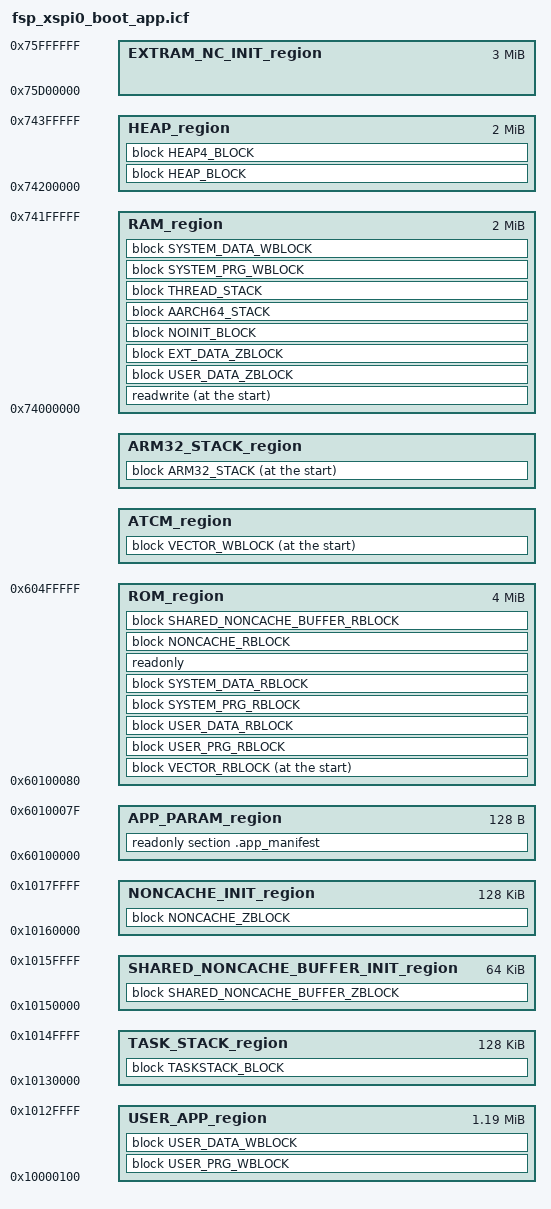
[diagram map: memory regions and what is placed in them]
/*=============================================================================
 * fsp_xspi0_boot_app.icf
 *
 * IAR linker configuration for the App half of the Loader+App split.
 *
 * Strictly aligned with the source rzn2l_xspi_boot.icf "primary" branch in
 * the ATCM-defined + no-USE_HRAM configuration (which is what RZN2L EK52
 * with PROFINET-IRT actually compiles into).
 *
 * Source-compatible blocks are exposed to the Loader through .app_manifest:
 *
 *   APP image in xSPI0 flash @ 0x60100000               Loader copies to
 *   --------------------------------------               -----------------
 *   [.app_manifest 0x80 bytes]                           (read in place)
 *   [VECTOR_RBLOCK]      vector table init       ----->  ATCM @ 0x00000000
 *   [USER_PRG_RBLOCK]    ro code                  ----->  USER_PRG_WBLOCK
 *   [USER_DATA_RBLOCK]   .rodata/.data inits      ----->  USER_DATA_WBLOCK
 *   [SYSTEM_PRG_RBLOCK]  obsd*.o ro code          ----->  SYSTEM_PRG_WBLOCK
 *   [SYSTEM_DATA_RBLOCK] obsd*.o data inits       ----->  SYSTEM_DATA_WBLOCK
 *   [NONCACHE_RBLOCK]    initialized noncache     ----->  NONCACHE_WBLOCK
 *   [SHARED_NONCACHE_BUFFER_RBLOCK]               ----->  SHARED_NONCACHE_BUFFER_WBLOCK
 *   [readonly catch-all]                                 (read in place)
 *
 * Runtime layout (after Loader has finished copying and jumped to 0x00):
 *
 *   ATCM           0x00000000 - 0x0001FFFF  (128 KB)
 *      VECTOR_WBLOCK  (reset vector + 15 exception vectors)
 *
 *   BTCM           0x00100000 - 0x0011FFFF  (128 KB)
 *      0x00103F88  ARM32_STACK (exception mode stacks: SYS/SVC/IRQ/FIQ/UND/ABT)
 *                  SVC_STACK at 0x00104388, matching source project layout
 *
 *   SystemRAM      0x10000000 - 0x1017FFFF  (1.5 MB)
 *      0x10000100  USER_PRG_WBLOCK + USER_DATA_WBLOCK    (USER_APP_region)
 *      0x10130000  TASKSTACK_BLOCK                       (TASK_STACK_region)
 *      0x10150000  SHARED_NONCACHE_BUFFER_*              (source-compatible)
 *      0x10160000  NONCACHE_ZBLOCK / NONCACHE_WBLOCK     (.noncache_buffer*)
 *
 *   SDRAM CS2 cacheable  0x74000000 - 0x77FFFFFF (32 MB W9825G6KH-6)
 *      0x74000000  USER_DATA_ZBLOCK + EXT_DATA_ZBLOCK
 *                  + NOINIT_BLOCK + AARCH64_STACK + THREAD_STACK
 *                                                          (RAM_region, 2 MB)
 *                  + SYSTEM_PRG_WBLOCK + SYSTEM_DATA_WBLOCK
 *      0x74200000  HEAP_BLOCK + HEAP4_BLOCK                (HEAP_region, 2 MB)
 *      0x75D00000  EXTRAMNC_BLOCK (mirrored to 0x55D00000 noncache view)
 *
 *=============================================================================*/

include "memory_regions.icf";

/*-----------------------------------------------------------------------------*/
/*  Symbols / addresses                                                        */
/*-----------------------------------------------------------------------------*/

define symbol APP_FLASH_START          = 0x60100000;
define symbol APP_FLASH_SIZE           = 0x00400000;       /* 4 MB           */

define symbol APP_MANIFEST_SIZE        = 0x00000080;       /* see app_manifest.c */

/* Mirrors source's "ATCM defined, no USE_HRAM" branch:                       */
/*   INTVEC_ADDRESS = ATCM_PRV_START                                          */
/*   USER_APP       = [0x10000100, 0x1012FFFF]   (SystemRAM, ~1.2 MB)         */
/*   TASK_STACK     = [0x10130000, 0x1014FFFF]   (SystemRAM, 128 KB)          */
/*   RAM_region     = [CS2 + 0,    CS2 + 0x1FFFFF] = [0x74000000, 0x741FFFFF] */
/*   HEAP_region    = [0x74200000, 0x743FFFFF]   (2 MB)                       */
/*   EXTRAM_NC      = CS2_top - 0x300000 = 0x75D00000 (mirrored from 0x55D00000) */

define symbol INTVEC_ADDRESS           = ATCM_CR52_0_START;       /* 0x00000000  */
define symbol ATCM_REGION_SIZE         = ATCM_CR52_0_LENGTH;      /* 0x00020000  */

define symbol ARM32_STACK_START        = BTCM_CR52_0_START + 0x00003F88;
define symbol ARM32_STACK_END          = ARM32_STACK_START + 0x000017FF;

define symbol USER_APP_START           = 0x10000100;
define symbol USER_APP_END             = 0x1012FFFF;

define symbol TASK_STACK_START         = 0x10130000;
define symbol TASK_STACK_END           = 0x1014FFFF;

define symbol CS2_BASE                 = 0x74000000;
define symbol RSK_SDRAM_SIZE           = 0x02000000;     /* 32 MB W9825G6KH-6 */
define symbol EXTRAM_NC_SIZE           = 0x00300000;     /* 3 MB              */
define symbol EXTERNAL_RAM_MIRROR_OFFSET = 0x20000000;   /* cached <-> noncache */

define symbol RAM_region_START         = CS2_BASE;                                  /* 0x74000000 */
define symbol RAM_region_END           = CS2_BASE + 0x001FFFFF;                     /* 0x741FFFFF */

define symbol HEAP_region_START        = 0x74200000;
define symbol HEAP_region_END          = 0x743FFFFF;

define symbol NONCACHE_INIT_START      = 0x10160000;
define symbol NONCACHE_INIT_END        = 0x1017FFFF;
define symbol NONCACHE_RUNTIME_START   = 0x30160000;

define symbol SHARED_NONCACHE_INIT_START    = 0x10150000;
define symbol SHARED_NONCACHE_INIT_END      = 0x1015FFFF;
define symbol SHARED_NONCACHE_RUNTIME_START = 0x30150000;

/* EXTRAM_NC runtime sits at the TOP 3 MB of physical SDRAM via the noncache  */
/* CS2 mirror (0x54000000 = CS2 - 0x20000000). The init image lives at the    */
/* same physical SDRAM cells viewed through the cached alias, so IAR can      */
/* link-place the bytes during build.                                         */
define symbol EXTRAM_NC_NC_START       = (CS2_BASE - EXTERNAL_RAM_MIRROR_OFFSET) + RSK_SDRAM_SIZE - EXTRAM_NC_SIZE;
                                                                                    /* 0x55D00000 */
define symbol EXTRAM_NC_C_START        =  CS2_BASE                              + RSK_SDRAM_SIZE - EXTRAM_NC_SIZE;
                                                                                    /* 0x75D00000 */

/*-----------------------------------------------------------------------------*/
/*  Memory + Regions                                                           */
/*-----------------------------------------------------------------------------*/

define memory mem with size = 4G;

define region APP_PARAM_region       = mem:[from APP_FLASH_START                     size APP_MANIFEST_SIZE];
define region ROM_region             = mem:[from APP_FLASH_START + APP_MANIFEST_SIZE  size APP_FLASH_SIZE - APP_MANIFEST_SIZE];
define region ATCM_region            = mem:[from INTVEC_ADDRESS                      size ATCM_REGION_SIZE];
define region ARM32_STACK_region     = mem:[from ARM32_STACK_START                   to   ARM32_STACK_END];
define region USER_APP_region        = mem:[from USER_APP_START                      to   USER_APP_END];
define region TASK_STACK_region      = mem:[from TASK_STACK_START                    to   TASK_STACK_END];
define region RAM_region             = mem:[from RAM_region_START                    to   RAM_region_END];
define region HEAP_region            = mem:[from HEAP_region_START                   to   HEAP_region_END];
define region NONCACHE_INIT_region   = mem:[from NONCACHE_INIT_START                 to   NONCACHE_INIT_END];
define region SHARED_NONCACHE_BUFFER_INIT_region = mem:[from SHARED_NONCACHE_INIT_START to SHARED_NONCACHE_INIT_END];
define region EXTRAM_NC_INIT_region  = mem:[from EXTRAM_NC_C_START                   size EXTRAM_NC_SIZE];

/*=============================================================================*/
/*  B L O C K   L A Y O U T                                                    */
/*=============================================================================*/

/*-----------------------------------------------------------------------------*/
/*  Vector table (16 entries x 0x80)                                           */
/*-----------------------------------------------------------------------------*/

define block VECTOR_RBLOCK with fixed order
{
    block VECTOR_RBLOCK_0x000 with alignment = 0x80 { ro code section .intvec_init       },
    block VECTOR_RBLOCK_0x080 with alignment = 0x80 { ro code section .intvec_0x080_init },
    block VECTOR_RBLOCK_0x100 with alignment = 0x80 { ro code section .intvec_0x100_init },
    block VECTOR_RBLOCK_0x180 with alignment = 0x80 { ro code section .intvec_0x180_init },
    block VECTOR_RBLOCK_0x200 with alignment = 0x80 { ro code section .intvec_0x200_init },
    block VECTOR_RBLOCK_0x280 with alignment = 0x80 { ro code section .intvec_0x280_init },
    block VECTOR_RBLOCK_0x300 with alignment = 0x80 { ro code section .intvec_0x300_init },
    block VECTOR_RBLOCK_0x380 with alignment = 0x80 { ro code section .intvec_0x380_init },
    block VECTOR_RBLOCK_0x400 with alignment = 0x80 { ro code section .intvec_0x400_init },
    block VECTOR_RBLOCK_0x480 with alignment = 0x80 { ro code section .intvec_0x480_init },
    block VECTOR_RBLOCK_0x500 with alignment = 0x80 { ro code section .intvec_0x500_init },
    block VECTOR_RBLOCK_0x580 with alignment = 0x80 { ro code section .intvec_0x580_init },
    block VECTOR_RBLOCK_0x600 with alignment = 0x80 { ro code section .intvec_0x600_init },
    block VECTOR_RBLOCK_0x680 with alignment = 0x80 { ro code section .intvec_0x680_init },
    block VECTOR_RBLOCK_0x700 with alignment = 0x80 { ro code section .intvec_0x700_init },
    block VECTOR_RBLOCK_0x780 with alignment = 0x80 { ro code section .intvec_0x780_init }
};

define block VECTOR_WBLOCK with fixed order
{
    block VECTOR_WBLOCK_0x000 with alignment = 0x80 { rw code section .intvec       },
    block VECTOR_WBLOCK_0x080 with alignment = 0x80 { rw code section .intvec_0x080 },
    block VECTOR_WBLOCK_0x100 with alignment = 0x80 { rw code section .intvec_0x100 },
    block VECTOR_WBLOCK_0x180 with alignment = 0x80 { rw code section .intvec_0x180 },
    block VECTOR_WBLOCK_0x200 with alignment = 0x80 { rw code section .intvec_0x200 },
    block VECTOR_WBLOCK_0x280 with alignment = 0x80 { rw code section .intvec_0x280 },
    block VECTOR_WBLOCK_0x300 with alignment = 0x80 { rw code section .intvec_0x300 },
    block VECTOR_WBLOCK_0x380 with alignment = 0x80 { rw code section .intvec_0x380 },
    block VECTOR_WBLOCK_0x400 with alignment = 0x80 { rw code section .intvec_0x400 },
    block VECTOR_WBLOCK_0x480 with alignment = 0x80 { rw code section .intvec_0x480 },
    block VECTOR_WBLOCK_0x500 with alignment = 0x80 { rw code section .intvec_0x500 },
    block VECTOR_WBLOCK_0x580 with alignment = 0x80 { rw code section .intvec_0x580 },
    block VECTOR_WBLOCK_0x600 with alignment = 0x80 { rw code section .intvec_0x600 },
    block VECTOR_WBLOCK_0x680 with alignment = 0x80 { rw code section .intvec_0x680 },
    block VECTOR_WBLOCK_0x700 with alignment = 0x80 { rw code section .intvec_0x700 },
    block VECTOR_WBLOCK_0x780 with alignment = 0x80 { rw code section .intvec_0x780 }
};

/*-----------------------------------------------------------------------------*/
/*  USER program: FSP drivers + application glue (SRAM-resident)               */
/*  Everything except obsd* PROFINET stack and a few special sections.         */
/*-----------------------------------------------------------------------------*/

define block USER_PRG_RBLOCK with alignment = 8
{
    ro code
}
except
{
    ro code object obsd*.o,
    ro code section .intvec_init,
    ro code section .intvec_0x080_init, ro code section .intvec_0x100_init,
    ro code section .intvec_0x180_init, ro code section .intvec_0x200_init,
    ro code section .intvec_0x280_init, ro code section .intvec_0x300_init,
    ro code section .intvec_0x380_init, ro code section .intvec_0x400_init,
    ro code section .intvec_0x480_init, ro code section .intvec_0x500_init,
    ro code section .intvec_0x580_init, ro code section .intvec_0x600_init,
    ro code section .intvec_0x680_init, ro code section .intvec_0x700_init,
    ro code section .intvec_0x780_init
};

define block USER_PRG_WBLOCK with alignment = 8
{
    rw code
}
except
{
    rw code object obsd*.o,
    rw code section .intvec,
    rw code section .intvec_0x080, rw code section .intvec_0x100,
    rw code section .intvec_0x180, rw code section .intvec_0x200,
    rw code section .intvec_0x280, rw code section .intvec_0x300,
    rw code section .intvec_0x380, rw code section .intvec_0x400,
    rw code section .intvec_0x480, rw code section .intvec_0x500,
    rw code section .intvec_0x580, rw code section .intvec_0x600,
    rw code section .intvec_0x680, rw code section .intvec_0x700,
    rw code section .intvec_0x780
};

define block USER_DATA_RBLOCK with fixed order, alignment = 8
{
    block USER_DATA_RBLOCK0 with alignment = 8 { section .rodata_init         },
    block USER_DATA_RBLOCK1 with alignment = 8 { section __DLIB_PERTHREAD_init },
    block USER_DATA_RBLOCK2 with alignment = 8 { section .data_init           },
    block USER_DATA_RBLOCK3 with alignment = 8 { section .version_init        }
}
except
{
    section .rodata_init       object obsd*.o,
    section .data_init         object obsd*.o
};

define block USER_DATA_WBLOCK with fixed order, alignment = 8
{
    block USER_DATA_WBLOCK0 with alignment = 8 { section .rodata          },
    block USER_DATA_WBLOCK1 with alignment = 8 { section __DLIB_PERTHREAD },
    block USER_DATA_WBLOCK2 with alignment = 8 { section .data            },
    block USER_DATA_WBLOCK3 with alignment = 8 { section .version         }
}
except
{
    section .rodata object obsd*.o,
    section .data   object obsd*.o
};

/*-----------------------------------------------------------------------------*/
/*  SYSTEM program: PROFINET (obsd*.o) - SDRAM-resident (bulky)                */
/*-----------------------------------------------------------------------------*/

define block SYSTEM_PRG_RBLOCK with alignment = 8
{
    ro code object obsd*.o
};

define block SYSTEM_PRG_WBLOCK with alignment = 8
{
    rw code object obsd*.o
};

define block SYSTEM_DATA_RBLOCK with fixed order, alignment = 8
{
    block SYSTEM_DATA_RBLOCK0 with alignment = 8 { section .rodata_init object obsd*.o },
    block SYSTEM_DATA_RBLOCK1 with alignment = 8 { section .data_init   object obsd*.o }
};

define block SYSTEM_DATA_WBLOCK with fixed order, alignment = 8
{
    block SYSTEM_DATA_WBLOCK0 with alignment = 8 { section .rodata object obsd*.o },
    block SYSTEM_DATA_WBLOCK1 with alignment = 8 { section .data   object obsd*.o }
};

/*-----------------------------------------------------------------------------*/
/*  Zero-init / uninitialised / stack blocks                                   */
/*-----------------------------------------------------------------------------*/

define block USER_DATA_ZBLOCK with alignment = 8 { };
define block EXT_DATA_ZBLOCK  with alignment = 4 { section .bss, section xdata_d_tcm };
define block NOINIT_BLOCK     with alignment = 8 { zeroinit };

define block ARM32_STACK with fixed order
{
    block SYS_STACK with alignment = 8 { rw section .sys_stack },
    block SVC_STACK with alignment = 8 { rw section .svc_stack },
    block IRQ_STACK with alignment = 8 { rw section .irq_stack },
    block FIQ_STACK with alignment = 8 { rw section .fiq_stack },
    block UND_STACK with alignment = 8 { rw section .und_stack },
    block ABT_STACK with alignment = 8 { rw section .abt_stack }
};
define block AARCH64_STACK   with alignment = 8 { rw section .aarch64_stack* };
define block THREAD_STACK    with alignment = 8 { rw section .stack*         };
define block TASKSTACK_BLOCK with alignment = 4 { section task_stack         };

define block HEAP_BLOCK   with alignment = 8 { rw section HEAP              };
define block HEAP4_BLOCK  with alignment = 4 { section .bss object heap_4.o };

define block EXTRAMNC_BLOCK with alignment = 32 { section nocache, section uncached_mem };

/*-----------------------------------------------------------------------------*/
/*  NONCACHE blocks, matching source rzn2l_xspi_boot.icf naming.              */
/*-----------------------------------------------------------------------------*/

define block NONCACHE_RBLOCK with fixed order, alignment = 32
{
    block USER_DATA_NONCACHE_RBLOCK with alignment = 8 { section .data_noncache*_init },
    block DMAC_LINK_MODE_RBLOCK with alignment = 8 { section .dmac_link_mode*_init },
    block NONCACHE_BUFFER_RBLOCK with alignment = 32 { section .noncache_buffer*_init }
};

define block NONCACHE_WBLOCK with fixed order
{
    block USER_DATA_NONCACHE_WBLOCK with alignment = 8 { section .data_noncache* },
    block DMAC_LINK_MODE_WBLOCK with alignment = 8 { section .dmac_link_mode* },
    block NONCACHE_BUFFER_WBLOCK with alignment = 32 { section .noncache_buffer* }
};

define block NONCACHE_ZBLOCK with fixed order
{
    block USER_DATA_NONCACHE_ZBLOCK with alignment = 8 { zi section .data_noncache* },
    block DMAC_LINK_MODE_ZBLOCK with alignment = 8 { zi section .dmac_link_mode* },
    block NONCACHE_BUFFER_ZBLOCK with alignment = 32 { zi section .noncache_buffer* }
};

define block SHARED_NONCACHE_BUFFER_RBLOCK with alignment = 32 { section .shared_noncache_buffer*_init };
define block SHARED_NONCACHE_BUFFER_WBLOCK with alignment = 32 { section .shared_noncache_buffer* };
define block SHARED_NONCACHE_BUFFER_ZBLOCK with alignment = 32 { zi section .shared_noncache_buffer* };

/*=============================================================================*/
/*  S P E C I F Y I N G   I N I T I A L I Z A T I O N                          */
/*=============================================================================*/

initialize manually
{
    ro code,
    section .data,
    section __DLIB_PERTHREAD,
    section .rodata,
    section .version,
    section .data_noncache*,
    section .dmac_link_mode*,
    section .noncache_buffer*,
    section .shared_noncache_buffer*,
    section .data_extramnc*
};

do not initialize { zeroinit, section .noinit };

/*=============================================================================*/
/*  S E C T I O N   L A Y O U T                                                */
/*=============================================================================*/

/*-----------------------------------------------------------------------------*/
/*  Flash (xSPI0 CS0)                                                          */
/*  Order:                                                                     */
/*    [0x60100000] .app_manifest    (128 bytes, read in place by Loader)       */
/*    [0x60100080] VECTOR_RBLOCK    (vector table init image)                  */
/*                USER_PRG_RBLOCK / USER_DATA_RBLOCK                           */
/*                SYSTEM_PRG_RBLOCK / SYSTEM_DATA_RBLOCK                       */
/*                NONCACHE_RBLOCK / SHARED_NONCACHE_BUFFER_RBLOCK              */
/*                readonly catch-all                                           */
/*-----------------------------------------------------------------------------*/

place in APP_PARAM_region          { readonly section .app_manifest };

place at start of ROM_region       { block VECTOR_RBLOCK };
place in ROM_region                {
    block USER_PRG_RBLOCK,
    block USER_DATA_RBLOCK,
    block SYSTEM_PRG_RBLOCK,
    block SYSTEM_DATA_RBLOCK,
    readonly,
    block NONCACHE_RBLOCK,
    block SHARED_NONCACHE_BUFFER_RBLOCK
};

/*-----------------------------------------------------------------------------*/
/*  ATCM @ 0x00000000   (vector table runtime location, matches source ATCM    */
/*                       branch INTVEC_ADDRESS = ATCM_PRV_START)               */
/*-----------------------------------------------------------------------------*/

place at start of ATCM_region      { block VECTOR_WBLOCK };

/*-----------------------------------------------------------------------------*/
/*  SystemRAM   USER_APP_region = 0x10000100 - 0x1012FFFF                      */
/*-----------------------------------------------------------------------------*/

place in USER_APP_region           { block USER_PRG_WBLOCK };
place in USER_APP_region           { block USER_DATA_WBLOCK };

place at start of ARM32_STACK_region
                                   { block ARM32_STACK };

place in TASK_STACK_region         { block TASKSTACK_BLOCK };

/*-----------------------------------------------------------------------------*/
/*  SDRAM (CS2 cacheable)                                                      */
/*    RAM_region [0x74000000, 0x741FFFFF]:                                     */
/*      zero-init blocks + AArch64/thread stacks + SYSTEM_PRG/DATA_WBLOCK      */
/*    HEAP_region [0x74200000, 0x743FFFFF]:                                    */
/*      HEAP_BLOCK + HEAP4_BLOCK                                               */
/*    EXTRAM_NC_INIT_region [0x75D00000, 0x75FFFFFF]:                          */
/*      EXTRAMNC_BLOCK (mirrored to 0x55D00000 noncache view)                  */
/*-----------------------------------------------------------------------------*/

place at start of RAM_region       { readwrite };

place in RAM_region
{
    block USER_DATA_ZBLOCK,
    block EXT_DATA_ZBLOCK,
    block NOINIT_BLOCK,
    block AARCH64_STACK,
    block THREAD_STACK
};

place in RAM_region                { block SYSTEM_PRG_WBLOCK };
place in RAM_region                { block SYSTEM_DATA_WBLOCK };

place in HEAP_region               { block HEAP_BLOCK, block HEAP4_BLOCK };

place in NONCACHE_INIT_region with mirroring to NONCACHE_RUNTIME_START
                                   { block NONCACHE_WBLOCK };
place in NONCACHE_INIT_region      { block NONCACHE_ZBLOCK };

place in SHARED_NONCACHE_BUFFER_INIT_region with mirroring to SHARED_NONCACHE_RUNTIME_START
                                   { block SHARED_NONCACHE_BUFFER_WBLOCK };
place in SHARED_NONCACHE_BUFFER_INIT_region
                                   { block SHARED_NONCACHE_BUFFER_ZBLOCK };

place in EXTRAM_NC_INIT_region with mirroring to EXTRAM_NC_NC_START
                                   { block EXTRAMNC_BLOCK };

/*=============================================================================*/
/*  E X P O R T E D   S Y M B O L S                                            */
/*=============================================================================*/

define exported symbol __region_APP_FLASH_start__  = APP_FLASH_START;
define exported symbol __region_INTVEC_start__     = INTVEC_ADDRESS;
define exported symbol __region_USER_APP_start__   = USER_APP_START;
define exported symbol __region_TASK_STACK_start__ = TASK_STACK_START;
define exported symbol __region_RAM_start__        = RAM_region_START;
define exported symbol __region_HEAP_start__       = HEAP_region_START;
define exported symbol __region_NONCACHE_start__   = NONCACHE_RUNTIME_START;
define exported symbol __region_EXTRAM_NC_start__  = EXTRAM_NC_NC_START;
